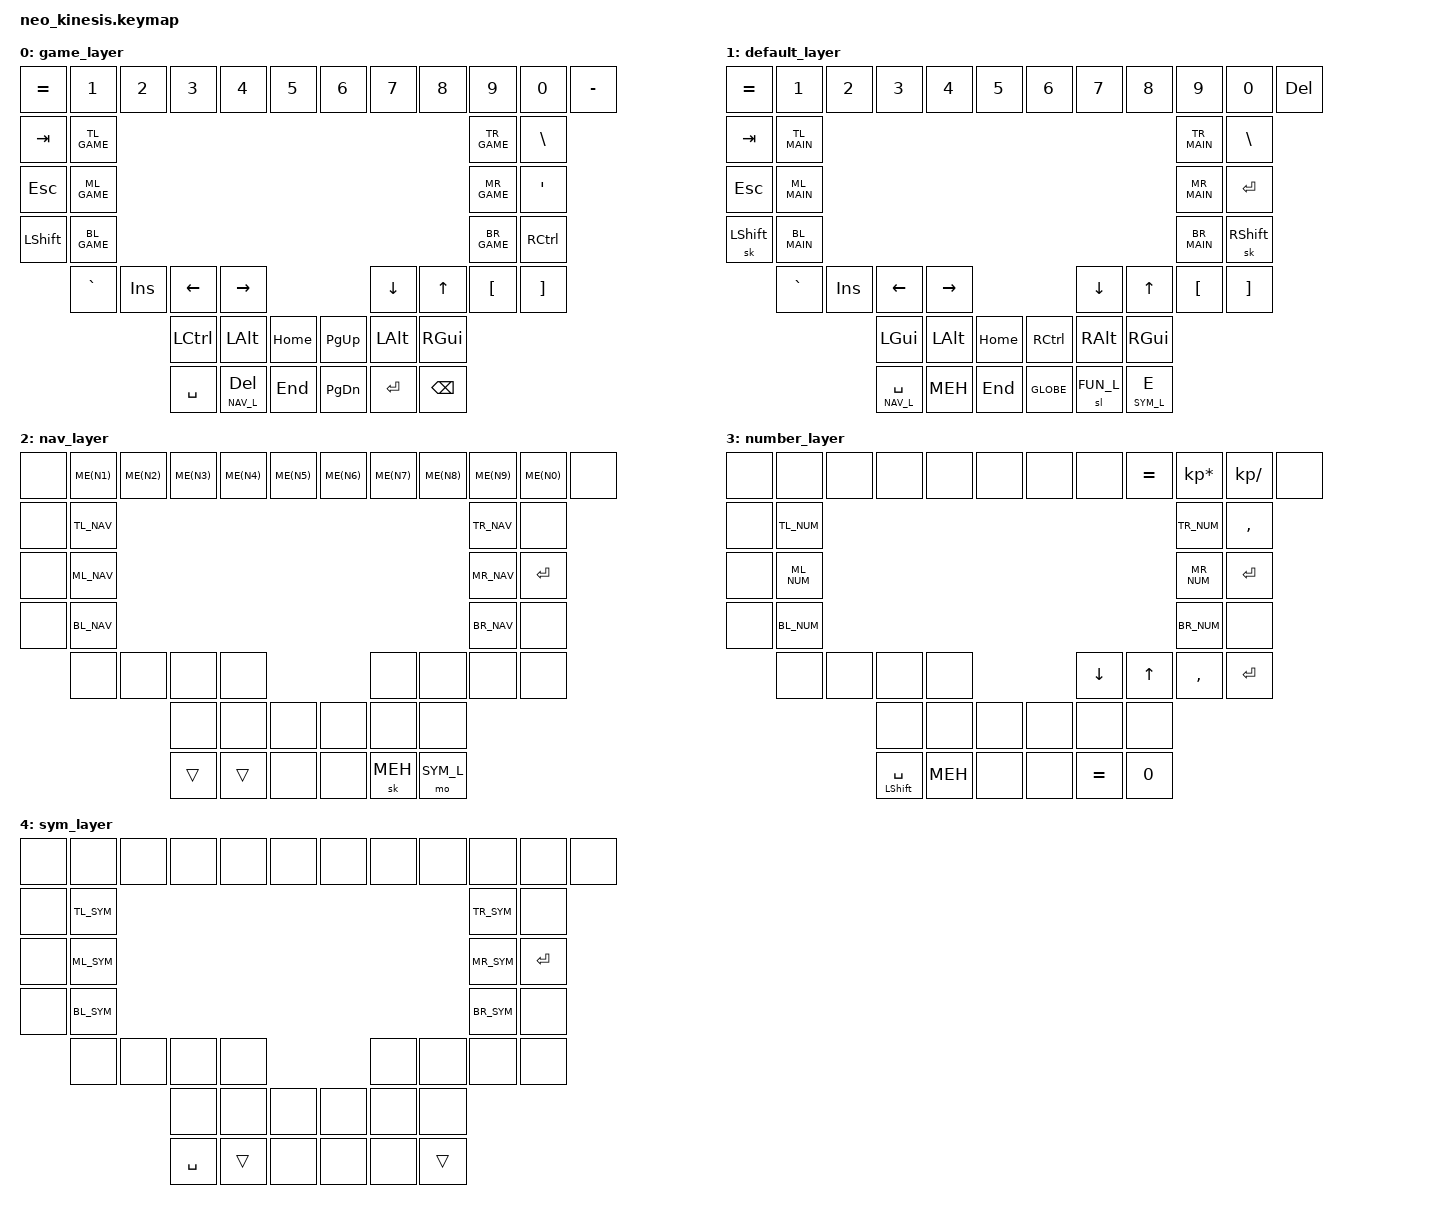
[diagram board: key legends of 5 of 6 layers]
#include <behaviors.dtsi>
#include <dt-bindings/zmk/keys.h>
#include <dt-bindings/zmk/bt.h>
#include <dt-bindings/zmk/outputs.h>

#include "zmk-helpers/helper.h"
#include "./fingers.dtsi"

#include "../../../merlinvn/config.dtsi"
#include "../../../merlinvn/macros.dtsi"
#include "../../../merlinvn/behaviors.dtsi"
#include "../../../merlinvn/combos.dtsi"
#include "../../../merlinvn/keymap.dtsi"

#define BT(n) BT_SEL n

//  0  - 5  6  - 11
//  12 - 17 18 - 23
//  24 - 29 30 - 35
//  36 - 41 42 - 47
//  48 - 51 52 - 55
//  56 - 61 62 - 67

/ {
    keymap {
        compatible = "zmk,keymap";

        game_layer {

            bindings = <
    &kp EQUAL  &kp N1   &kp N2   &kp N3    &kp N4    &kp N5            &kp N6    &kp N7    &kp N8    &kp N9    &kp N0   &kp MINUS
    &kp TAB    TL_GAME                                  TR_GAME                                              &kp BSLH
    &kp ESC    ML_GAME                                  MR_GAME                                              &kp SQT
    &kp LSHIFT BL_GAME                                  BR_GAME                                              &kp RCTRL
             &kp GRAVE  &kp INS  &kp LEFT  &kp RIGHT                             &kp DOWN  &kp UP    &kp LBKT  &kp RBKT
                                 &kp LCTRL &kp LALT  &kp HOME          &kp PG_UP &kp LALT  &kp RGUI
                                 &kp SPACE  &lt NAV_L DEL  &kp END     &kp PG_DN &kp RET   &kp BSPC
            >;
        };

        default_layer {

            bindings = <
    &kp EQUAL   &kp N1      &kp N2     &kp N3     &kp N4    &kp N5            &kp N6    &kp N7     &kp N8     &kp N9      &kp N0      &kp DEL
    &kp TAB     TL_MAIN    TR_MAIN    &kp BSLH
    &kp ESC     ML_MAIN    MR_MAIN    &kp RET
    &sk LSHFT   BL_MAIN    BR_MAIN    &sk RSHFT
               &kp GRAVE   &kp INS    &kp LEFT  &kp RIGHT                               &kp DOWN     &kp UP   &kp LBKT   &kp RBKT
                                 &kp LGUI   &kp LALT   &kp HOME                         &kp RCTL &kp RALT      &kp RGUI
                           &lt NAV_L SPACE  &kp MEH  &kp END                          &kp GLOBE &sl FUN_L     &lt SYM_L E
            >;
        };



        nav_layer {

            bindings = <
    &none   &kp ME(N1)  &kp ME(N2) &kp ME(N3)       &kp ME(N4)   &kp ME(N5)           &kp ME(N6)   &kp ME(N7) &kp ME(N8) &kp ME(N9)    &kp ME(N0)  &none
    &none   TL_NAV      TR_NAV     &none
    &none   ML_NAV      MR_NAV     &kp RET
    &none   BL_NAV      BR_NAV     &none
            &none       &none    &none  &none                                          &none     &none       &none         &none
                                 &none  &none  &none                                  &none  &none  &none
                                 &trans  &trans  &none                                &none  &sk MEH &mo SYM_L
            >;
        };

        number_layer {

            bindings = <
    &none  &none     &none     &none      &none     &none                 &none         &none     &kp EQUAL  &kp KP_MULTIPLY  &kp KP_DIVIDE &none
    &none  TL_NUM     TR_NUM  &kp COMMA
    &none  ML_NUM     MR_NUM   &kp RET
    &none  BL_NUM     BR_NUM   &none
           &none     &none     &none      &none                                         &kp DOWN  &kp UP     &kp COMMA    &kp RET
                                 &none  &none  &none             &none  &none      &none
                                 &mt LSHIFT SPACE  &kp MEH  &none        &none  &kp EQUAL  &kp N0
            >;
        };

        sym_layer {

            bindings = <
    &none  &none     &none      &none      &none     &none                 &none      &none      &none     &none      &none      &none
    &none  TL_SYM    TR_SYM     &none
    &none  ML_SYM    MR_SYM     &kp RET
    &none  BL_SYM    BR_SYM     &none
           &none     &none     &none      &none                                    &none  &none  &none  &none
                                 &none   &none  &none        &none  &none   &none
                              &kp SPACE  &trans  &none        &none  &none   &trans
            >;
        };

        fn_layer {
            bindings = <
    &bt BT_CLR  &bt BT(0)  &bt BT(1)  &bt BT(2)  &bt BT(3)  &bt BT(4)                &none  &out OUT_TOG  &out OUT_BLE  &out OUT_USB  &sys_reset    &bootloader
    &none  TL_FUN                 TR_FUN      &none
    &none  ML_FUN                 MR_FUN      &none
    &none  BL_FUN                 BR_FUN      &none
           &none     &none     &none      &none                                         &kp C_PLAY_PAUSE &kp C_PREV &kp C_NEXT &kp C_STOP
                                 &none  &none  &none            &none  &none  &none
                                &kp SPACE  &kp HYPR  &none        &none  &trans  &none
            >;
        };


    };
};
